VERSION ""

NS_ :

BS_:

BU_: PCM CAV

BO_ 1077 PcmToCav6: 8 PCM
 SG_ PcmToCav6_RC : 57|2@0+ (1,0) [0|3] "" Vector__XXX

BO_ 1061 CavToPcmLongCtrl6: 8 CAV
 SG_ CavToPcmLong6_PV : 24|31@0+ (1,0) [0|2147483647] "" Vector__XXX
 SG_ CavToPcmLong6_RC : 57|2@0+ (1,0) [0|3] "" Vector__XXX

BO_ 1060 CavToPcmLongCtrl5: 8 CAV
 SG_ CavToPcmLong5_PV : 24|31@0+ (1,0) [0|2147483647] "" Vector__XXX
 SG_ CavToPcmLong5_RC : 57|2@0+ (1,0) [0|3] "" Vector__XXX

BO_ 1059 CavToPcmLongCtrl4: 8 CAV
 SG_ CavToPcmLong4_PV : 24|31@0+ (1,0) [0|2147483647] "" Vector__XXX
 SG_ CavToPcmLong4_RC : 57|2@0+ (1,0) [0|3] "" Vector__XXX

BO_ 1045 CavToPcmLateralCtrl6: 8 CAV
 SG_ CavToPcmLat6_RC : 57|2@0+ (1,0) [0|3] "" Vector__XXX
 SG_ CavToPcmLat6_PV : 24|31@0+ (1,0) [0|2147483647] "" Vector__XXX

BO_ 1044 CavToPcmLateralCtrl5: 8 CAV
 SG_ CavToPcmLat5_RC : 57|2@0+ (1,0) [0|3] "" Vector__XXX
 SG_ CavToPcmLat5_PV : 24|31@0+ (1,0) [0|2147483647] "" Vector__XXX

BO_ 1043 CavToPcmLateralCtrl4: 8 CAV
 SG_ CavToPcmLat4_PV : 24|31@0+ (1,0) [0|2147483647] "" Vector__XXX
 SG_ CavToPcmLat4_RC : 57|2@0+ (1,0) [0|3] "" Vector__XXX

BO_ 1058 CavToPcmLongCtrl3: 8 CAV
 SG_ CavToPcmLong3_PV : 24|31@0+ (1,0) [0|2147483647] "" Vector__XXX
 SG_ CavToPcmLong3_RC : 57|2@0+ (1,0) [0|3] "" Vector__XXX

BO_ 1057 CavToPcmLongCtrl2: 8 CAV
 SG_ CavToPcmLong2_PV : 24|31@0+ (1,0) [0|2147483647] "" Vector__XXX
 SG_ CavToPcmLong2_RC : 57|2@0+ (1,0) [0|3] "" Vector__XXX

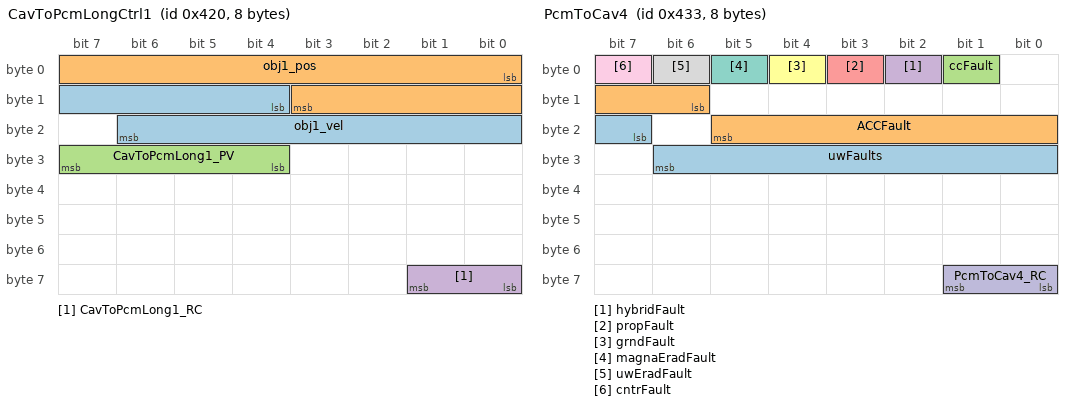
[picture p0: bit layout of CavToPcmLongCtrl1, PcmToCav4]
BO_ 1056 CavToPcmLongCtrl1: 8 CAV
 SG_ obj1_vel : 12|11@1- (0.125,0) [-128|127.875] "" Vector__XXX
 SG_ obj1_pos : 0|12@1+ (0.125,0) [-256|255.875] "" Vector__XXX
 SG_ CavToPcmLong1_PV : 31|4@0+ (1,0) [0|2147480000] "" Vector__XXX
 SG_ CavToPcmLong1_RC : 57|2@0+ (1,0) [0|3] "" Vector__XXX

BO_ 1042 CavToPcmLateralCtrl3: 8 CAV
 SG_ CavToPcmLat3_RC : 57|2@0+ (1,0) [0|3] "" Vector__XXX
 SG_ CavToPcmLat3_PV : 24|31@0+ (1,0) [0|2147483647] "" Vector__XXX

BO_ 1041 CavToPcmLateralCtrl2: 8 CAV
 SG_ CavToPcmLat2_RC : 57|2@0+ (1,0) [0|3] "" Vector__XXX
 SG_ CavToPcmLat2_PV : 24|31@0+ (1,0) [0|2147483647] "" Vector__XXX

BO_ 1040 CavToPcmLateralCtrl1: 8 CAV
 SG_ CavToPcmLat1_PV : 24|31@0+ (1,0) [0|2147483647] "" Vector__XXX
 SG_ CavToPcmLat1_RC : 57|2@0+ (1,0) [0|3] "" Vector__XXX

BO_ 1076 PcmToCav5: 8 PCM
 SG_ PcmToCav5_RC : 57|2@0+ (1,0) [0|3] "" Vector__XXX

BO_ 1075 PcmToCav4: 8 PCM
 SG_ uwFaults : 23|8@1+ (1,0) [0|0] "" Vector__XXX
 SG_ ACCFault : 14|8@1+ (1,0) [0|0] "" Vector__XXX
 SG_ ccFault : 1|1@1+ (1,0) [0|0] "" Vector__XXX
 SG_ hybridFault : 2|1@1+ (1,0) [0|0] "" Vector__XXX
 SG_ propFault : 3|1@1+ (1,0) [0|0] "" Vector__XXX
 SG_ grndFault : 4|1@1+ (1,0) [0|0] "" Vector__XXX
 SG_ magnaEradFault : 5|1@1+ (1,0) [0|0] "" Vector__XXX
 SG_ uwEradFault : 6|1@1+ (1,0) [0|0] "" Vector__XXX
 SG_ cntrFault : 7|1@1+ (1,0) [0|0] "" Vector__XXX
 SG_ PcmToCav4_RC : 57|2@0+ (1,0) [0|3] "" Vector__XXX

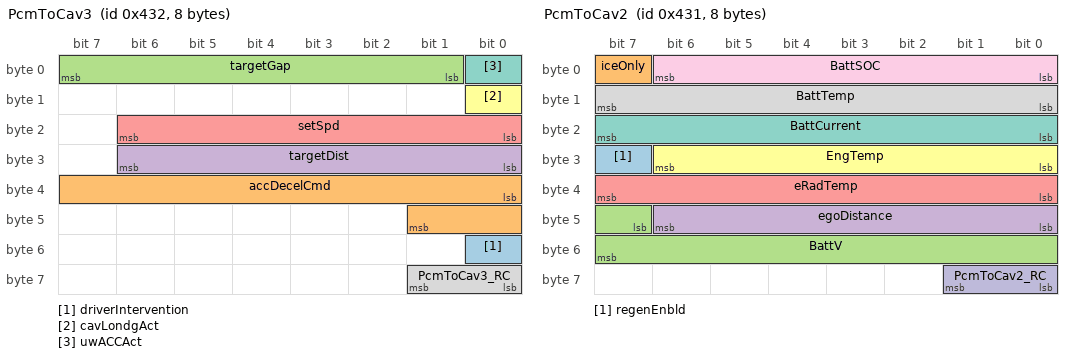
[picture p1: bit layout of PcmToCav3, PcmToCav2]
BO_ 1074 PcmToCav3: 8 PCM
 SG_ driverIntervention : 48|1@1+ (1,0) [0|0] "" Vector__XXX
 SG_ accDecelCmd : 32|10@1- (0.01,0) [-5.12|5.11] "" Vector__XXX
 SG_ targetGap : 1|7@1+ (1,0) [0|0] "" Vector__XXX
 SG_ targetDist : 24|7@1+ (1,0) [0|127] "" Vector__XXX
 SG_ setSpd : 16|7@1+ (1,0) [0|127] "" Vector__XXX
 SG_ cavLondgAct : 8|1@1+ (1,0) [0|0] "" Vector__XXX
 SG_ uwACCAct : 0|1@1+ (1,0) [0|0] "" Vector__XXX
 SG_ PcmToCav3_RC : 57|2@0+ (1,0) [0|3] "" Vector__XXX

BO_ 1073 PcmToCav2: 8 PCM
 SG_ regenEnbld : 31|1@1+ (1,0) [0|1] "" Vector__XXX
 SG_ iceOnly : 7|1@1+ (1,0) [0|0] "" Vector__XXX
 SG_ BattV : 47|9@1+ (1,0) [0|511] "" Vector__XXX
 SG_ egoDistance : 40|7@1+ (1,0) [0|127] "" Vector__XXX
 SG_ eRadTemp : 32|8@1+ (1,0) [0|255] "" Vector__XXX
 SG_ EngTemp : 24|7@1+ (1,0) [0|255] "" Vector__XXX
 SG_ BattCurrent : 16|8@1+ (1,0) [-128|127] "" Vector__XXX
 SG_ BattTemp : 8|8@1+ (1,0) [0|255] "" Vector__XXX
 SG_ BattSOC : 0|7@1+ (1,0) [0|127] "%" Vector__XXX
 SG_ PcmToCav2_RC : 57|2@0+ (1,0) [0|3] "" Vector__XXX

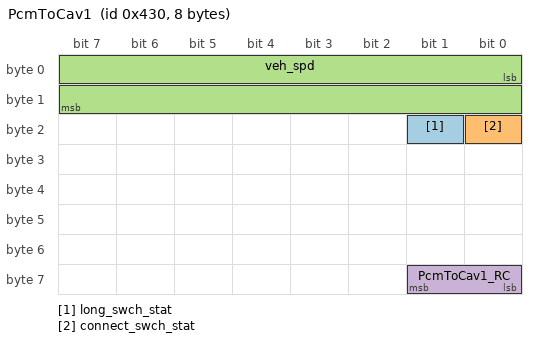
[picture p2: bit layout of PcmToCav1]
BO_ 1072 PcmToCav1: 8 PCM
 SG_ long_swch_stat : 17|1@1+ (1,0) [0|1] "" Vector__XXX
 SG_ connect_swch_stat : 16|1@1+ (1,0) [0|1] "" Vector__XXX
 SG_ veh_spd : 0|16@1+ (0.001,0) [0|65.535] "" Vector__XXX
 SG_ PcmToCav1_RC : 57|2@0+ (1,0) [0|3] "" Vector__XXX

BA_DEF_ BO_  "AppGenMsgCycleTime" INT 0 0;
BA_DEF_DEF_  "AppGenMsgCycleTime" 0;
BA_ "AppGenMsgCycleTime" BO_ 1077 20;
BA_ "AppGenMsgCycleTime" BO_ 1061 40;
BA_ "AppGenMsgCycleTime" BO_ 1060 40;
BA_ "AppGenMsgCycleTime" BO_ 1059 40;
BA_ "AppGenMsgCycleTime" BO_ 1045 40;
BA_ "AppGenMsgCycleTime" BO_ 1044 40;
BA_ "AppGenMsgCycleTime" BO_ 1043 40;
BA_ "AppGenMsgCycleTime" BO_ 1058 40;
BA_ "AppGenMsgCycleTime" BO_ 1057 40;
BA_ "AppGenMsgCycleTime" BO_ 1056 40;
BA_ "AppGenMsgCycleTime" BO_ 1042 40;
BA_ "AppGenMsgCycleTime" BO_ 1041 40;
BA_ "AppGenMsgCycleTime" BO_ 1040 40;
BA_ "AppGenMsgCycleTime" BO_ 1076 20;
BA_ "AppGenMsgCycleTime" BO_ 1075 20;
BA_ "AppGenMsgCycleTime" BO_ 1074 20;
BA_ "AppGenMsgCycleTime" BO_ 1073 20;
BA_ "AppGenMsgCycleTime" BO_ 1072 20;
